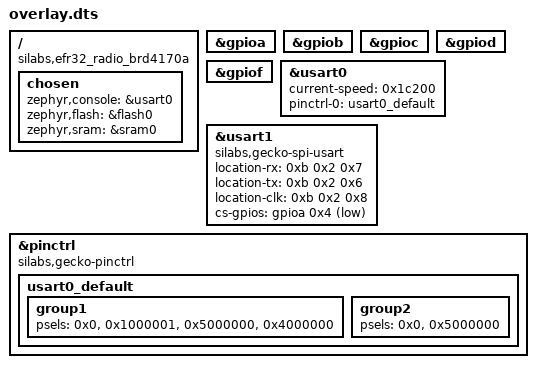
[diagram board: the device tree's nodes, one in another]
/ {
	compatible = "silabs,efr32_radio_brd4170a", "silabs,efr32mg12p";
	chosen {
		zephyr,console = &usart0;
		zephyr,flash = &flash0;
		zephyr,sram = &sram0;
	};
};
&gpioa{
	status = "okay";
};
&gpiob{
	status = "okay";
};
&gpioc{
	status = "okay";
};
&gpiod{
	status = "okay";
};
&gpiof{
	status = "okay";
};
&usart0{
	status = "okay";
	current-speed = < 0x1c200 >;
	pinctrl-0 = < &usart0_default >;
	pinctrl-names = "default";
};
&usart1{
	compatible = "silabs,gecko-spi-usart";
	status = "okay";
	#address-cells = < 0x1 >;
	#size-cells = < 0x0 >;
	location-rx = < 0xb 0x2 0x7 >;
	location-tx = < 0xb 0x2 0x6 >;
	location-clk = < 0xb 0x2 0x8 >;
	cs-gpios = < &gpioa 0x4 0x1 >;
};
&pinctrl{
	compatible = "silabs,gecko-pinctrl";
	usart0_default: usart0_default {
		group1 {
			psels = < 0x0 >, < 0x1000001 >, < 0x5000000 >, < 0x4000000 >;
		};
		group2 {
			psels = < 0x0 >, < 0x5000000 >;
		};
	};
};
